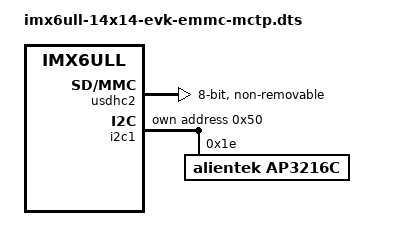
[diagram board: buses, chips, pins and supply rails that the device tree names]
/*
 * Copyright 2019 NXP
 *
 * This program is free software; you can redistribute it and/or
 * modify it under the terms of the GNU General Public License
 * as published by the Free Software Foundation; either version 2
 * of the License, or (at your option) any later version.
 */

#include "imx6ull-14x14-evk-mctp.dts"
#include "dt-bindings/i2c/i2c.h"

&usdhc2 {
	pinctrl-names = "default", "state_100mhz", "state_200mhz";
	pinctrl-0 = <&pinctrl_usdhc2_8bit>;
	pinctrl-1 = <&pinctrl_usdhc2_8bit_100mhz>;
	pinctrl-2 = <&pinctrl_usdhc2_8bit_200mhz>;
	bus-width = <8>;
	non-removable;
	status = "okay";
};

&i2c1 {
	mctp-controller;
	// status = "okay";

	// #define I2C_OWN_SLAVE_ADDRESS	(1 << 30)
	
	mctp_i2c1@50 {
		compatible = "mctp-i2c-controller";
		reg = <(0x50 | I2C_OWN_SLAVE_ADDRESS)>;
	};
	//
	// 可能是因为已经有了 mctp_i2c1@50, 如果再加 i2c-slave-mqueue@13, 会报错;
	// 静态指定
	// i2c-slave-mqueue@13 {
	// 	compatible = "slave-mqueue";
	// 	reg = <(0x13 | I2C_OWN_SLAVE_ADDRESS)>;
	// 	i2c-protocol;
	// };

	/*正点原子imx6ull 开发板*/
	ap3216c@1e {
		compatible = "alientek,ap3216c";
		reg = <0x1e>;
	};
};

&i2c2 {
	// 静态指定
	// i2c-slave-mqueue@13 {
	// 	compatible = "slave-mqueue";
	// 	reg = <(0x13 | I2C_OWN_SLAVE_ADDRESS)>;
	// 	i2c-protocol;
	// };
};

// 设备树居然也支持 #if 0 语法;
// 查看 i2c2 的全貌;
#if 0
i2c2: i2c@21a4000 {
	#address-cells = <1>;
	#size-cells = <0>;
	compatible = "fsl,imx6ul-i2c", "fsl,imx21-i2c";
	reg = <0x021a4000 0x4000>;
	interrupts = <GIC_SPI 37 IRQ_TYPE_LEVEL_HIGH>;
	clocks = <&clks IMX6UL_CLK_I2C2>;
	clock-frequency = <100000>;
	pinctrl-names = "default";
	pinctrl-0 = <&pinctrl_i2c2>;
	status = "okay";

	codec: wm8960@1a {
		#sound-dai-cells = <0>;
		compatible = "wlf,wm8960";
		reg = <0x1a>;
		wlf,shared-lrclk;
		wlf,hp-cfg = <3 2 3>;
		wlf,gpio-cfg = <1 3>;
		clocks = <&clks IMX6UL_CLK_SAI2>;
		clock-names = "mclk";
	};

	ov5640: ov5640@3c {
		compatible = "ovti,ov5640";
		reg = <0x3c>;
		pinctrl-names = "default";
		pinctrl-0 = <&pinctrl_csi1 &pinctrl_camera_clock>;
		clocks = <&clks IMX6UL_CLK_CSI>;
		clock-names = "csi_mclk";
		pwn-gpios = <&gpio_spi 6 1>;
		rst-gpios = <&gpio_spi 5 0>;
		csi_id = <0>;
		mclk = <24000000>;
		mclk_source = <0>;
		status = "disabled";
		port {
			ov5640_ep: endpoint {
				remote-endpoint = <&csi1_ep>;
			};
		};
	};
};
#endif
